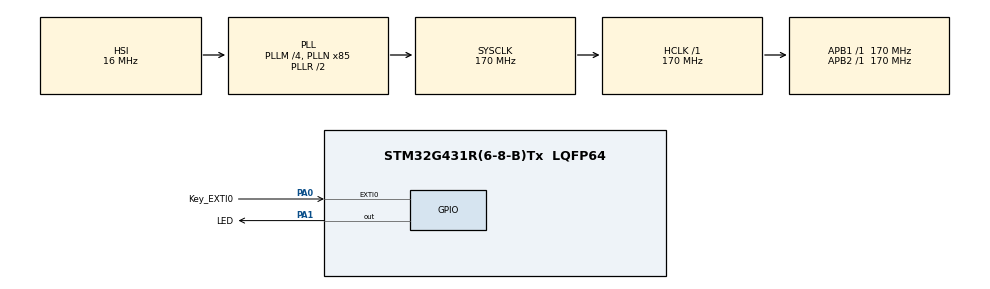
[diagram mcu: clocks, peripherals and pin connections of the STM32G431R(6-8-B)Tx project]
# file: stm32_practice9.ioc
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Mcu.Family=STM32G4
Mcu.Name=STM32G431R(6-8-B)Tx
Mcu.Package=LQFP64
NVIC.EXTI0_IRQn=true\:10\:0\:true\:false\:true\:true\:true\:true
NVIC.PriorityGroup=NVIC_PRIORITYGROUP_4
PA0.GPIO_Label=Key_EXTI0
PA0.GPIO_ModeDefaultEXTI=GPIO_MODE_IT_FALLING
PA0.GPIO_PuPd=GPIO_PULLUP
PA0.Signal=GPXTI0
PA1.GPIO_Label=LED
PA1.GPIO_PuPd=GPIO_PULLUP
PA1.PinState=GPIO_PIN_SET
PA1.Signal=GPIO_Output
PA13.Mode=Serial_Wire
PA13.Signal=SYS_JTMS-SWDIO
PA14.Mode=Serial_Wire
PA14.Signal=SYS_JTCK-SWCLK
PC14-OSC32_IN.Mode=LSE-External-Oscillator
PC14-OSC32_IN.Signal=RCC_OSC32_IN
PC15-OSC32_OUT.Mode=LSE-External-Oscillator
PC15-OSC32_OUT.Signal=RCC_OSC32_OUT
PF0-OSC_IN.Mode=HSE-External-Oscillator
PF0-OSC_IN.Signal=RCC_OSC_IN
PF1-OSC_OUT.Mode=HSE-External-Oscillator
PF1-OSC_OUT.Signal=RCC_OSC_OUT
ProjectManager.HeapSize=0x200
ProjectManager.StackSize=0x400
ProjectManager.TargetToolchain=STM32CubeIDE
RCC.ADC12Freq_Value=170000000
RCC.AHBFreq_Value=170000000
RCC.APB1Freq_Value=170000000
RCC.APB1TimFreq_Value=170000000
RCC.APB2Freq_Value=170000000
RCC.APB2TimFreq_Value=170000000
RCC.CortexFreq_Value=170000000
RCC.EXTERNAL_CLOCK_VALUE=12288000
RCC.HCLKFreq_Value=170000000
RCC.HSE_VALUE=8000000
RCC.HSI48_VALUE=48000000
RCC.HSI_VALUE=16000000
RCC.PLLM=RCC_PLLM_DIV4
RCC.PLLN=85
RCC.SYSCLKFreq_VALUE=170000000
RCC.SYSCLKSource=RCC_SYSCLKSOURCE_PLLCLK
RCC.USBFreq_Value=170000000
RCC.VCOOutputFreq_Value=340000000
VP_SYS_VS_DBSignals.Mode=DisableDeadBatterySignals
board=custom

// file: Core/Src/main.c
/* USER CODE BEGIN Header */
/**
  ******************************************************************************
  * @file           : main.c
  * @brief          : Main program body
  ******************************************************************************
  * @attention
  *
  * Copyright (c) 2026 STMicroelectronics.
  * All rights reserved.
  *
  * This software is licensed under terms that can be found in the LICENSE file
  * in the root directory of this software component.
  * If no LICENSE file comes with this software, it is provided AS-IS.
  *
  ******************************************************************************
  */
/* USER CODE END Header */
#include "main.h"

/* USER CODE BEGIN PV */
volatile uint8_t key_pressed_flag = 0;//定义按键状态变量
/* USER CODE END PV */

void SystemClock_Config(void);
static void MX_GPIO_Init(void);

int main(void)
{

  /* MCU Configuration--------------------------------------------------------*/

  /* Reset of all peripherals, Initializes the Flash interface and the Systick. */
  HAL_Init();

  /* Configure the system clock */
  SystemClock_Config();

  /* Initialize all configured peripherals */
  MX_GPIO_Init();

  /* Infinite loop */
  /* USER CODE BEGIN WHILE */
  while (1)
  {
	  if(key_pressed_flag == 1)//判断按键状态
	  {
		  HAL_Delay(20);//延时消抖
		  if(HAL_GPIO_ReadPin(GPIOA, Key_EXTI0_Pin) == GPIO_PIN_RESET)//再次检测按键状态，确认按键按下
		  {
			  HAL_GPIO_TogglePin(GPIOA, LED_Pin);//翻转LED状态
		  }
		  key_pressed_flag = 0;//清除标志位
	  }
    /* USER CODE END WHILE */

  }
}

void SystemClock_Config(void)
{
  RCC_OscInitTypeDef RCC_OscInitStruct = {0};
  RCC_ClkInitTypeDef RCC_ClkInitStruct = {0};

  /** Configure the main internal regulator output voltage
  */
  HAL_PWREx_ControlVoltageScaling(PWR_REGULATOR_VOLTAGE_SCALE1_BOOST);

  /** Initializes the RCC Oscillators according to the specified parameters
  * in the RCC_OscInitTypeDef structure.
  */
  RCC_OscInitStruct.OscillatorType = RCC_OSCILLATORTYPE_HSI;
  RCC_OscInitStruct.HSIState = RCC_HSI_ON;
  RCC_OscInitStruct.HSICalibrationValue = RCC_HSICALIBRATION_DEFAULT;
  RCC_OscInitStruct.PLL.PLLState = RCC_PLL_ON;
  RCC_OscInitStruct.PLL.PLLSource = RCC_PLLSOURCE_HSI;
  RCC_OscInitStruct.PLL.PLLM = RCC_PLLM_DIV4;
  RCC_OscInitStruct.PLL.PLLN = 85;
  RCC_OscInitStruct.PLL.PLLP = RCC_PLLP_DIV2;
  RCC_OscInitStruct.PLL.PLLQ = RCC_PLLQ_DIV2;
  RCC_OscInitStruct.PLL.PLLR = RCC_PLLR_DIV2;
  if (HAL_RCC_OscConfig(&RCC_OscInitStruct) != HAL_OK)
  {
    Error_Handler();
  }

  /** Initializes the CPU, AHB and APB buses clocks
  */
  RCC_ClkInitStruct.ClockType = RCC_CLOCKTYPE_HCLK|RCC_CLOCKTYPE_SYSCLK
                              |RCC_CLOCKTYPE_PCLK1|RCC_CLOCKTYPE_PCLK2;
  RCC_ClkInitStruct.SYSCLKSource = RCC_SYSCLKSOURCE_PLLCLK;
  RCC_ClkInitStruct.AHBCLKDivider = RCC_SYSCLK_DIV1;
  RCC_ClkInitStruct.APB1CLKDivider = RCC_HCLK_DIV1;
  RCC_ClkInitStruct.APB2CLKDivider = RCC_HCLK_DIV1;

  if (HAL_RCC_ClockConfig(&RCC_ClkInitStruct, FLASH_LATENCY_4) != HAL_OK)
  {
    Error_Handler();
  }
}

static void MX_GPIO_Init(void)
{
  GPIO_InitTypeDef GPIO_InitStruct = {0};

  /* GPIO Ports Clock Enable */
  __HAL_RCC_GPIOC_CLK_ENABLE();
  __HAL_RCC_GPIOF_CLK_ENABLE();
  __HAL_RCC_GPIOA_CLK_ENABLE();

  /*Configure GPIO pin Output Level */
  HAL_GPIO_WritePin(LED_GPIO_Port, LED_Pin, GPIO_PIN_SET);

  /*Configure GPIO pin : Key_EXTI0_Pin */
  GPIO_InitStruct.Pin = Key_EXTI0_Pin;
  GPIO_InitStruct.Mode = GPIO_MODE_IT_FALLING;
  GPIO_InitStruct.Pull = GPIO_PULLUP;
  HAL_GPIO_Init(Key_EXTI0_GPIO_Port, &GPIO_InitStruct);

  /*Configure GPIO pin : LED_Pin */
  GPIO_InitStruct.Pin = LED_Pin;
  GPIO_InitStruct.Mode = GPIO_MODE_OUTPUT_PP;
  GPIO_InitStruct.Pull = GPIO_PULLUP;
  GPIO_InitStruct.Speed = GPIO_SPEED_FREQ_LOW;
  HAL_GPIO_Init(LED_GPIO_Port, &GPIO_InitStruct);

  /* EXTI interrupt init*/
  HAL_NVIC_SetPriority(EXTI0_IRQn, 10, 0);
  HAL_NVIC_EnableIRQ(EXTI0_IRQn);

}

/* USER CODE BEGIN 4 */
void HAL_GPIO_EXTI_Callback(uint16_t GPIO_Pin)
{
	if(GPIO_Pin == Key_EXTI0_Pin)//如果中断来源是按键1
	{
		key_pressed_flag = 1;//设置标志位
	}
}
/* USER CODE END 4 */

void Error_Handler(void)
{
  __disable_irq();
  while (1)
  {
  }
}
